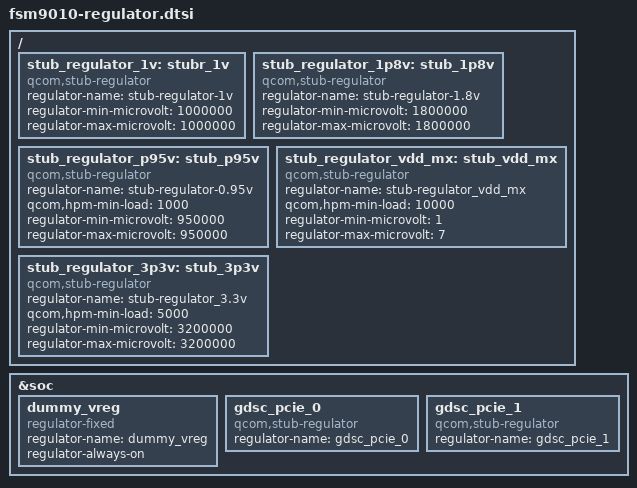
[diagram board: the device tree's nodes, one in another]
/* Copyright (c) 2014-2015, The Linux Foundation. All rights reserved.
 *
 * This program is free software; you can redistribute it and/or modify
 * it under the terms of the GNU General Public License version 2 and
 * only version 2 as published by the Free Software Foundation.
 *
 * This program is distributed in the hope that it will be useful,
 * but WITHOUT ANY WARRANTY; without even the implied warranty of
 * MERCHANTABILITY or FITNESS FOR A PARTICULAR PURPOSE.  See the
 * GNU General Public License for more details.
 */

/* Stub Regulator */
/ {
	/* PCIE1/2_0P9_VDDA; */
	stub_regulator_1v: stubr_1v {
		compatible = "qcom,stub-regulator";
		regulator-name = "stub-regulator-1v";
		regulator-min-microvolt = <1000000>;
		regulator-max-microvolt = <1000000>;
		status = "okay";
	};

	/* pcie LDO12 */
	stub_regulator_1p8v: stub_1p8v {
		compatible = "qcom,stub-regulator";
		regulator-name = "stub-regulator-1.8v";
		regulator-min-microvolt = <1800000>;
		regulator-max-microvolt = <1800000>;
		status = "okay";
	};

	stub_regulator_p95v: stub_p95v  {
		compatible = "qcom,stub-regulator";
		regulator-name = "stub-regulator-0.95v";
		qcom,hpm-min-load = <1000>;
		regulator-min-microvolt = <950000>;
		regulator-max-microvolt = <950000>;
	};

	stub_regulator_vdd_mx: stub_vdd_mx {
		compatible = "qcom,stub-regulator";
		regulator-name = "stub-regulator_vdd_mx";
		qcom,hpm-min-load = <10000>;
		regulator-min-microvolt = <1>;
		regulator-max-microvolt = <7>;
	};

	stub_regulator_3p3v: stub_3p3v {
		compatible = "qcom,stub-regulator";
		regulator-name = "stub-regulator_3.3v";
		qcom,hpm-min-load = <5000>;
		regulator-min-microvolt = <3200000>;
		regulator-max-microvolt = <3200000>;
	};
};

&soc {
	dummy_vreg: dummy_vreg {
		compatible = "regulator-fixed";
		status = "ok";
		regulator-name = "dummy_vreg";
		regulator-always-on;
	};

	gdsc_pcie_0:gdsc_pcie_0 {
		compatible = "qcom,stub-regulator";
		regulator-name = "gdsc_pcie_0";
		status = "ok";
	};

	gdsc_pcie_1:gdsc_pcie_1 {
		compatible = "qcom,stub-regulator";
		regulator-name = "gdsc_pcie_1";
		status = "ok";
	};
};
